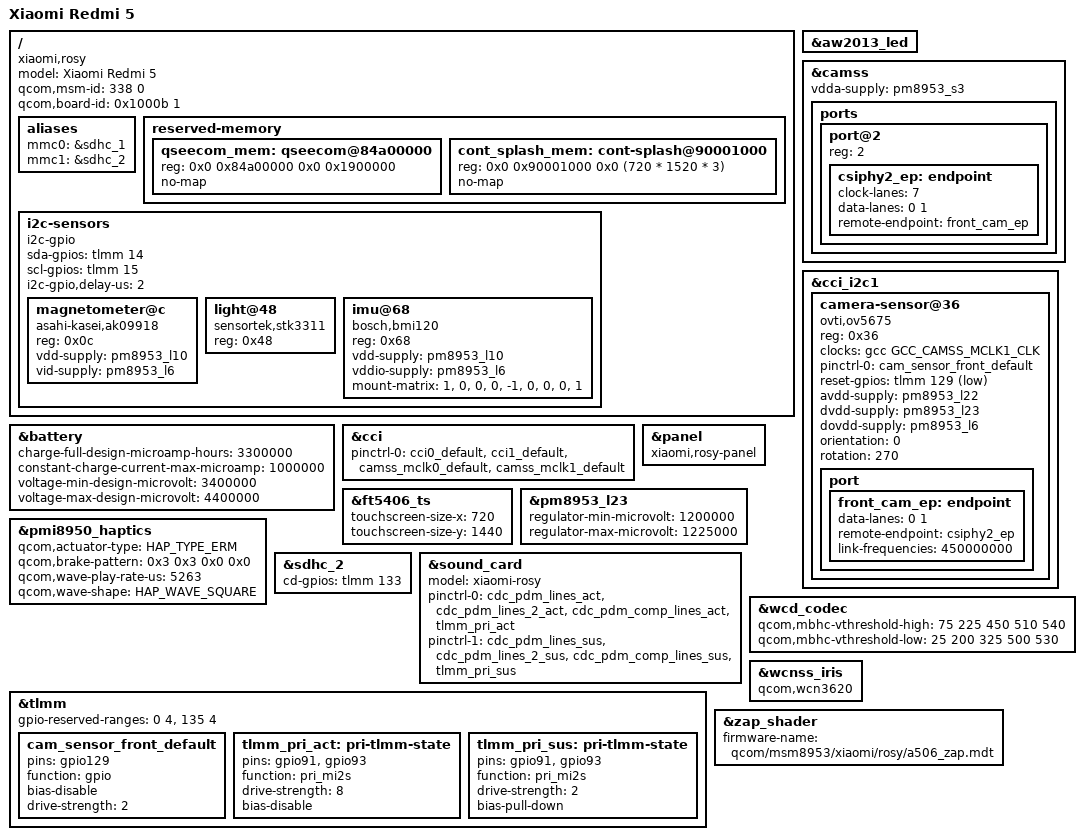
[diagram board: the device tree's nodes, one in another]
// SPDX-License-Identifier: BSD-3-Clause
/*
 * Copyright (c) 2024, Barnabas Czeman
 */
/dts-v1/;

#include "msm8953-xiaomi-common.dtsi"

/delete-node/ &cont_splash_mem;
/delete-node/ &qseecom_mem;

/ {
	model = "Xiaomi Redmi 5";
	compatible = "xiaomi,rosy", "qcom,sdm450";
	qcom,msm-id = <338 0>;
	qcom,board-id = <0x1000b 1>;

	aliases {
		mmc0 = &sdhc_1;
		mmc1 = &sdhc_2;
	};

	reserved-memory {
		qseecom_mem: qseecom@84a00000 {
			reg = <0x0 0x84a00000 0x0 0x1900000>;
			no-map;
		};

		cont_splash_mem: cont-splash@90001000 {
			reg = <0x0 0x90001000 0x0 (720 * 1520 * 3)>;
			no-map;
		};
	};

	i2c-sensors {
		compatible = "i2c-gpio";
		sda-gpios = <&tlmm 14 (GPIO_ACTIVE_HIGH|GPIO_OPEN_DRAIN)>;
		scl-gpios = <&tlmm 15 (GPIO_ACTIVE_HIGH|GPIO_OPEN_DRAIN)>;
		i2c-gpio,delay-us = <2>; /* ~100 kHz */
		#address-cells = <1>;
		#size-cells = <0>;

		magnetometer@c {
			compatible = "asahi-kasei,ak09918";
			reg = <0x0c>;

			vdd-supply = <&pm8953_l10>;
			vid-supply = <&pm8953_l6>;
		};

		light@48 {
			compatible = "sensortek,stk3311";
			reg = <0x48>;
		};

		imu@68 {
			compatible = "bosch,bmi120";
			reg = <0x68>;

			vdd-supply = <&pm8953_l10>;
			vddio-supply = <&pm8953_l6>;

			mount-matrix = "1", "0", "0",
					"0", "-1", "0",
					"0", "0", "1";
		};
	};
};

&aw2013_led {
	status = "okay";
};

&battery {
	charge-full-design-microamp-hours = <3300000>;
	constant-charge-current-max-microamp = <1000000>;
	voltage-min-design-microvolt = <3400000>;
	voltage-max-design-microvolt = <4400000>;
};

&camss {
	status = "okay";
	vdda-supply = <&pm8953_s3>;

	ports {
		port@2 {
			reg = <2>;
			csiphy2_ep: endpoint {
				clock-lanes = <7>;
				data-lanes = <0 1>;
				remote-endpoint = <&front_cam_ep>;
			};
		};
	};
};

&cci {
	pinctrl-0 = <&cci0_default>,
		    <&cci1_default>,
		    <&camss_mclk0_default>,
		    <&camss_mclk1_default>;
	pinctrl-names = "default";

	status = "okay";
};

&cci_i2c1 {
	camera-sensor@36 { // Front camera
		compatible = "ovti,ov5675";

		reg = <0x36>;

		clocks = <&gcc GCC_CAMSS_MCLK1_CLK>;

		pinctrl-0 = <&cam_sensor_front_default>;
		pinctrl-names = "default";

		reset-gpios = <&tlmm 129 GPIO_ACTIVE_LOW>;

		avdd-supply= <&pm8953_l22>;
		dvdd-supply = <&pm8953_l23>;
		dovdd-supply = <&pm8953_l6>;
		orientation = <0>;
		rotation = <270>;

		status = "okay";

		port {
			front_cam_ep: endpoint {
				data-lanes = <0 1>;
				remote-endpoint = <&csiphy2_ep>;
				link-frequencies = /bits/ 64 <450000000>;
			};
		};
	};
};

&ft5406_ts {
	status = "okay";

	touchscreen-size-x = <720>;
	touchscreen-size-y = <1440>;
};

&panel {
	compatible = "xiaomi,rosy-panel";
};

&pm8953_l23 {
	regulator-min-microvolt = <1200000>;
	regulator-max-microvolt = <1225000>;
};

&pmi8950_haptics {
	qcom,actuator-type = <HAP_TYPE_ERM>;
	qcom,brake-pattern = <0x3 0x3 0x0 0x0>;
	qcom,wave-play-rate-us = <5263>;
	qcom,wave-shape = <HAP_WAVE_SQUARE>;

	status = "okay";
};

&sdhc_2 {
	cd-gpios = <&tlmm 133 GPIO_ACTIVE_HIGH>;
};

&sound_card {
	model = "xiaomi-rosy";

	pinctrl-0 = <&cdc_pdm_lines_act
		&cdc_pdm_lines_2_act
		&cdc_pdm_comp_lines_act
		&tlmm_pri_act>;
	pinctrl-1 = <&cdc_pdm_lines_sus
		&cdc_pdm_lines_2_sus
		&cdc_pdm_comp_lines_sus
		&tlmm_pri_sus>;
	pinctrl-names = "default", "sleep";

	status = "okay";
};

&tlmm {
	gpio-reserved-ranges = <0 4>, <135 4>;

	cam_sensor_front_default: cam_sensor_front_default {
		pins = "gpio129";
		function = "gpio";
		bias-disable;
		drive-strength = <2>;
	};

	tlmm_pri_act: pri-tlmm-state {
		pins = "gpio91", "gpio93";
		function = "pri_mi2s";
		drive-strength = <8>;
		bias-disable;
	};

	tlmm_pri_sus: pri-tlmm-state {
		pins = "gpio91", "gpio93";
		function = "pri_mi2s";
		drive-strength = <2>;
		bias-pull-down;
	};

};

&wcd_codec {
	qcom,mbhc-vthreshold-high = <75 225 450 510 540>;
	qcom,mbhc-vthreshold-low = <25 200 325 500 530>;
	/delete-property/ qcom,gnd-jack-type-normally-open;
};

&wcnss_iris {
	compatible = "qcom,wcn3620";
};

&zap_shader {
	firmware-name = "qcom/msm8953/xiaomi/rosy/a506_zap.mdt";
};
